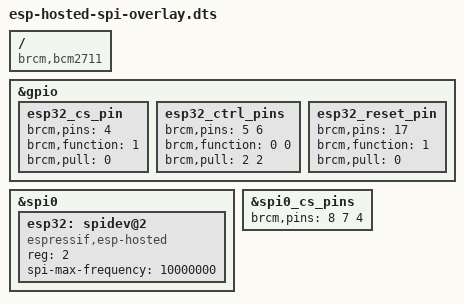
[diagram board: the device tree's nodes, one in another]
/*
 * Device Tree Overlay for ESP-Hosted SPI on RPi GPS Hat v4
 *
 * Configures ESP32-S3 as SPI slave alongside MCP2515 CAN controllers.
 *
 * SPI Bus Sharing:
 *   CE0 (GPIO8)  -> MCP2515 CAN0
 *   CE1 (GPIO7)  -> MCP2515 CAN1
 *   GPIO4        -> ESP32 CS (directly controlled)
 *
 * ESP32 Connections:
 *   RPi GPIO4  -> ESP32 IO10 (CS)
 *   RPi GPIO5  -> ESP32 IO3  (Handshake)
 *   RPi GPIO6  -> ESP32 IO4  (Data Ready)
 *   RPi GPIO17 -> ESP32 EN   (Reset)
 *   RPi GPIO10 -> ESP32 IO11 (MOSI)
 *   RPi GPIO9  -> ESP32 IO13 (MISO)
 *   RPi GPIO11 -> ESP32 IO12 (SCLK)
 *
 * Compile with:
 *   dtc -@ -I dts -O dtb -o esp-hosted-spi.dtbo esp-hosted-spi-overlay.dts
 *
 * Install:
 *   sudo cp esp-hosted-spi.dtbo /boot/firmware/overlays/
 *
 * Enable in /boot/firmware/config.txt:
 *   dtoverlay=esp-hosted-spi
 */

/dts-v1/;
/plugin/;

/ {
    compatible = "brcm,bcm2711";

    /* Configure GPIO4 as output for CS control */
    fragment@0 {
        target = <&gpio>;
        __overlay__ {
            esp32_cs_pin: esp32_cs_pin {
                brcm,pins = <4>;
                brcm,function = <1>;  /* Output */
                brcm,pull = <0>;      /* None */
            };

            esp32_ctrl_pins: esp32_ctrl_pins {
                brcm,pins = <5 6>;
                brcm,function = <0 0>;  /* Input */
                brcm,pull = <2 2>;      /* Pull-up */
            };

            esp32_reset_pin: esp32_reset_pin {
                brcm,pins = <17>;
                brcm,function = <1>;  /* Output */
                brcm,pull = <0>;      /* None */
            };
        };
    };

    /* Add ESP32 as spidev on CS2 (directly controlled via GPIO4) */
    fragment@1 {
        target = <&spi0>;
        __overlay__ {
            status = "okay";
            #address-cells = <1>;
            #size-cells = <0>;

            /*
             * ESP32 SPI slave
             * Note: reg = <2> means third device, CS controlled by driver/userspace
             * The esp-hosted driver controls GPIO4 directly for CS
             */
            esp32: spidev@2 {
                compatible = "espressif,esp-hosted";
                reg = <2>;
                spi-max-frequency = <10000000>;
                status = "okay";
            };
        };
    };

    /*
     * Add third chip select pin (GPIO4)
     * This extends SPI0 to support 3 CS lines
     */
    fragment@2 {
        target = <&spi0_cs_pins>;
        __overlay__ {
            brcm,pins = <8 7 4>;  /* CE0=GPIO8, CE1=GPIO7, CE2=GPIO4 */
        };
    };
};
